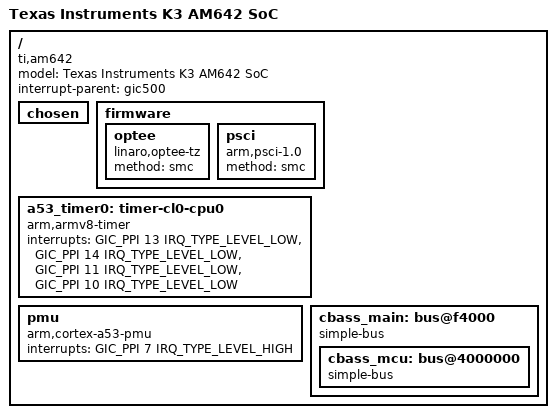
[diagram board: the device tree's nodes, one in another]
// SPDX-License-Identifier: GPL-2.0-only OR MIT
/*
 * Device Tree Source for AM642 SoC Family
 *
 * Copyright (C) 2020-2024 Texas Instruments Incorporated - https://www.ti.com/
 */

#include <dt-bindings/gpio/gpio.h>
#include <dt-bindings/interrupt-controller/irq.h>
#include <dt-bindings/interrupt-controller/arm-gic.h>
#include <dt-bindings/soc/ti,sci_pm_domain.h>

#include "k3-pinctrl.h"

/ {
	model = "Texas Instruments K3 AM642 SoC";
	compatible = "ti,am642";
	interrupt-parent = <&gic500>;
	#address-cells = <2>;
	#size-cells = <2>;

	chosen { };

	firmware {
		optee {
			compatible = "linaro,optee-tz";
			method = "smc";
		};

		psci: psci {
			compatible = "arm,psci-1.0";
			method = "smc";
		};
	};

	a53_timer0: timer-cl0-cpu0 {
		compatible = "arm,armv8-timer";
		interrupts = <GIC_PPI 13 IRQ_TYPE_LEVEL_LOW>, /* cntpsirq */
			     <GIC_PPI 14 IRQ_TYPE_LEVEL_LOW>, /* cntpnsirq */
			     <GIC_PPI 11 IRQ_TYPE_LEVEL_LOW>, /* cntvirq */
			     <GIC_PPI 10 IRQ_TYPE_LEVEL_LOW>; /* cnthpirq */
	};

	pmu: pmu {
		compatible = "arm,cortex-a53-pmu";
		interrupts = <GIC_PPI 7 IRQ_TYPE_LEVEL_HIGH>;
	};

	cbass_main: bus@f4000 {
		bootph-all;
		compatible = "simple-bus";
		#address-cells = <2>;
		#size-cells = <2>;
		ranges = <0x00 0x000f4000 0x00 0x000f4000 0x00 0x000002d0>, /* PINCTRL */
			 <0x00 0x00420000 0x00 0x00420000 0x00 0x00001000>, /* ESM0 */
			 <0x00 0x00600000 0x00 0x00600000 0x00 0x00001100>, /* GPIO */
			 <0x00 0x00a40000 0x00 0x00a40000 0x00 0x00000800>, /* Timesync router */
			 <0x00 0x00b00000 0x00 0x00b00000 0x00 0x00002400>, /* VTM */
			 <0x00 0x01000000 0x00 0x01000000 0x00 0x02330400>, /* First peripheral window */
			 <0x00 0x08000000 0x00 0x08000000 0x00 0x00200000>, /* Main CPSW */
			 <0x00 0x0d000000 0x00 0x0d000000 0x00 0x00800000>, /* PCIE_CORE */
			 <0x00 0x0e000000 0x00 0x0e000000 0x00 0x00000100>, /* Main RTI0 */
			 <0x00 0x0e010000 0x00 0x0e010000 0x00 0x00000100>, /* Main RTI1 */
			 <0x00 0x0f000000 0x00 0x0f000000 0x00 0x00c44200>, /* Second peripheral window */
			 <0x00 0x20000000 0x00 0x20000000 0x00 0x0a008000>, /* Third peripheral window */
			 <0x00 0x30000000 0x00 0x30000000 0x00 0x000bc100>, /* ICSSG0/1 */
			 <0x00 0x37000000 0x00 0x37000000 0x00 0x00040000>, /* TIMERMGR0 TIMERS */
			 <0x00 0x39000000 0x00 0x39000000 0x00 0x00000400>, /* CPTS0 */
			 <0x00 0x3b000000 0x00 0x3b000000 0x00 0x00000400>, /* GPMC0_CFG */
			 <0x00 0x3cd00000 0x00 0x3cd00000 0x00 0x00000200>, /* TIMERMGR0_CONFIG */
			 <0x00 0x3f004000 0x00 0x3f004000 0x00 0x00000400>, /* GICSS0_REGS */
			 <0x00 0x40900000 0x00 0x40900000 0x00 0x00030000>, /* SA2_UL0 */
			 <0x00 0x43000000 0x00 0x43000000 0x00 0x00020000>, /* CTRL_MMR0 */
			 <0x00 0x44043000 0x00 0x44043000 0x00 0x00000fe0>, /* TI SCI DEBUG */
			 <0x00 0x48000000 0x00 0x48000000 0x00 0x06400000>, /* DMASS */
			 <0x00 0x50000000 0x00 0x50000000 0x00 0x08000000>, /* GPMC0 DATA */
			 <0x00 0x60000000 0x00 0x60000000 0x00 0x08000000>, /* FSS0 DAT1 */
			 <0x00 0x68000000 0x00 0x68000000 0x00 0x08000000>, /* PCIe DAT0 */
			 <0x00 0x70000000 0x00 0x70000000 0x00 0x00200000>, /* OC SRAM */
			 <0x00 0x78000000 0x00 0x78000000 0x00 0x00800000>, /* Main R5FSS */
			 <0x01 0x00000000 0x01 0x00000000 0x00 0x00310000>, /* A53 PERIPHBASE */
			 <0x06 0x00000000 0x06 0x00000000 0x01 0x00000000>, /* PCIe DAT1 */
			 <0x05 0x00000000 0x05 0x00000000 0x01 0x00000000>, /* FSS0 DAT3 */

			 /* MCU Domain Range */
			 <0x00 0x04000000 0x00 0x04000000 0x00 0x01ff1400>;

		cbass_mcu: bus@4000000 {
			bootph-all;
			compatible = "simple-bus";
			#address-cells = <2>;
			#size-cells = <2>;
			ranges = <0x00 0x04000000 0x00 0x04000000 0x00 0x01ff1400>; /* Peripheral window */
		};
	};

	#include "k3-am64-thermal.dtsi"
};

/* Now include the peripherals for each bus segments */
#include "k3-am64-main.dtsi"
#include "k3-am64-mcu.dtsi"
